# A31L12x register map
Vendor: VENDOR ABOV Semiconductor Co., Ltd.; Series: A31L12x; File version: 1.0
CPU: CM0+ r0p1, little endian, no MPU, no FPU, VTOR, 2 interrupt priority bits
Registers are 32-bit, read-write, reset 0x0 unless marked. A register's access mark holds for its fields unless they carry their own. Offsets are from the block's base; [hi:lo] are bit positions; {n}, {i} and the like mark numbered series.

## ADC — High Speed 12 Bit A/D Converter
Base 0x40003000
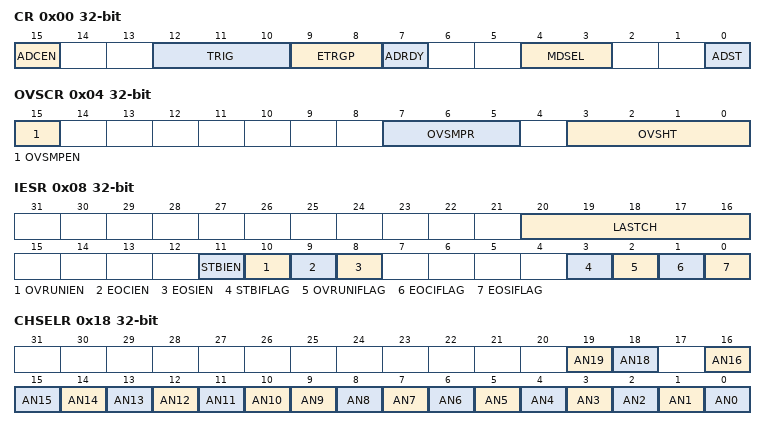
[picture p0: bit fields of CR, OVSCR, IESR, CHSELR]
0x00 CR — A/D Converter Control Register
  [15] ADCEN — ADC Module Enable
    0=Disable ADC Module Operation; 1=Enable ADC Module Operation
  [12:10] TRIG — ADC Trigger Signal Selection
    0=ADST (Select ADST.); {v}=TIMER{v+39} (Timer {v+39} Trigger Signals) (v=1..4); 7=ADTRG (External ADC Trigger Input)
  [9:8] ETRGP — ADC External Trigger Input Polarity Selection
    0=Disable ADC external trigger function; 1=FallingEdge (Trigger on falling edge); 2=RisingEdge (Trigger on rising edge); 3=BothEdge (Trigger on both of falling and rising edge)
  [7] ADRDY — ADC Conversion Ready
    0=Stop subsequent steps; 1=Ready to convert
  [4:3] MDSEL — ADC Conversion Mode Selection
    0=Single Conversion Mode; 1=Sequential Conversion Mode; 2=Continuous Conversion Mode
  [0] ADST — ADC Conversion Start
    0=NoEffect; 1=Start (Trigger signal generation for conversion start.)
0x04 OVSCR — A/D Converter Oversampling Control Register
  [15] OVSMPEN — Oversampling Enable
    0=Disable oversampling; 1=Enable oversampling
  [7:5] OVSMPR — Oversampling Ratio Selection
  [3:0] OVSHT — Oversampling Data Shift
    0=NoShift; {v}=ShiftRight{v}Bit (v=1..8)
0x08 IESR — A/D Converter Interrupt Enable and Status Register
  [20:16] LASTCH ro — ADC Last Conversion Channel Numbe
  [11] STBIEN — ADC Stabilization Interrupt Enable
    0=Disable stabilization interrupt; 1=Enable stabilization interrupt
  [10] OVRUNIEN — ADC Data Overrun Interrupt Enable
    0=Disable overrun interrupt; 1=Enable overrun interrupt
  [9] EOCIEN — ADC End of Conversion Interrupt Enable
    0=Disable end of conversion interrupt; 1=Enable end of conversion interrupt
  [8] EOSIEN — ADC End of Sequence Interrupt Enable
    0=Disable end of sequence interrupt; 1=Enable end of sequence interrupt
  [3] STBIFLAG — ADC Stabilization Interrupt Flag
    0=No request occurred; 1=Request occurred
  [2] OVRUNIFLAG — ADC Data Overrun Interrupt Flag
    0=No request occurred; 1=Request occurred
  [1] EOCIFLAG — ADC End of Conversion Interrupt Flag
    0=No request occurred; 1=Request occurred
  [0] EOSIFLAG — ADC End of Sequence Interrupt Flag
    0=No request occurred; 1=Request occurred
0x0C DR ro (reset mask 0xFFFF0000) — A/D Converter Data Register
  [15:0] ADDATA — A/D Converter Result Data
0x10 PREDR — A/D Converter Prescaler Data Register
  [3:0] PRED — A/D Converter Prescaler Data
0x14 SAMR — A/D Converter Sampling Time Register
  [4:0] SAMCK — Sampling Cycles for Sample/Hold Circuit
0x18 CHSELR — A/D Converter Channel Selection Register
  [all] fields
    0=NotSelected (ANx is not selected for conversion); 1=Selected (ANx is selected for conversion)
  [19] AN19 — AN19(BGR) Channel Selection
  [18] AN18 — AN18(AVDD) Channel Selection
  [16] AN16 — AN16(AVSS) Channel Selection
  [n] AN{n} (n=11..15) — AN{n} Channel Selection
  [10] AN10 — AN1 Channel Selection
  [n] AN{n} (n=0..9) — AN{n} Channel Selection

## CMPn — Comparator n
Base 0x53000000
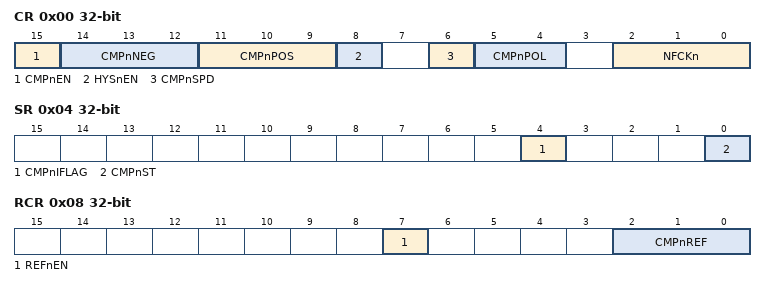
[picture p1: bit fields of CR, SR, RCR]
0x00 CR — Comparator n Control Register
  [15] CMPnEN — Comparator n Enable
    0=Disable comparator n operation; 1=Enable comparator n operation
  [14:12] CMPnNEG — Comparator n Negative Input Selection
    0=CPnN0 (Select external CPnN0 pin.); 1=CPnN1 (Select external CPnN1 pin.); 2=CPnN2 (Select external CPnN2 pin.); 3=CPnN3 (Select external CPnN3 pin. (Reserved on comparator 0)); 7=IntRef (Select internal reference.)
  [11:9] CMPnPOS — Comparator n Positive Input Selection
    0=CPnP0 (Select external CPnP0 pin.); 1=CPnP1 (Select external CPnP1 pin. (CP1POS signal on comparator 0)); {v}=CPnP{v} (Select external CPnP{v} pin. (Reserved on comparator 0)) (v=2..5)
  [8] HYSnEN — Comparator n Hysteresis Enable
    0=Disable hysteresis function; 1=Enable hysteresis function
  [6] CMPnSPD — Comparator n Speed Selection
    0=Slow speed; 1=Fast speed
  [5:4] CMPnPOL — Comparator n Interrupt Polarity Selection
    0=No interrupt at any edge; 1=FallingEdge (Interrupt on falling edge); 2=RisingEdge (Interrupt on rising edge); 3=BothEdge (Interrupt on both of falling and rising edge)
  [2:0] NFCKn — Comparator n Noise Filter Sampling Clock Selection
    0=PCLK1; 1=PCLK2; 2=PCLK4; 3=PCLK8; 4=PCLK16; 5=PCLK32; 6=PCLK64
0x04 SR — Comparator n Status Register
  [4] CMPnIFLAG — Comparator n Interrupt Flag
    0=No request occurred; 1=Request occurred. This bit is cleared to '0' when write '1'.
  [0] CMPnST ro — Comparator n Output Status
    0=Low (Comparator n output is low.); 1=High (Comparator n output is high.)
0x08 RCR — Comparator n Reference Control Register
  [7] REFnEN — Comparator n Internal Reference Enable
    0=Disable internal reference; 1=Enable internal reference
  [2:0] CMPnREF — Comparator n Reference Voltage Level Selection
    {v}={v+2}over11VDD (Select reference voltage level {v}. NOTE) Reference voltage = (2+k)xVDD/11, k: 0 to 7) (v=0..7)
